# AT32F413xx register map
Vendor: Keil; Series: AT32F413; File version: 1.0
CPU: CM4 r0p1, little endian, no MPU, FPU, 4 interrupt priority bits
Registers are 32-bit, read-write, reset 0x0 unless marked. A register's access mark holds for its fields unless they carry their own. Offsets are from the block's base; [hi:lo] are bit positions; {n}, {i} and the like mark numbered series; 'fields as' and 'values as' point back to an identical list.

## UART4 — Universal asynchronous receiver transmitter
Base 0x40004C00
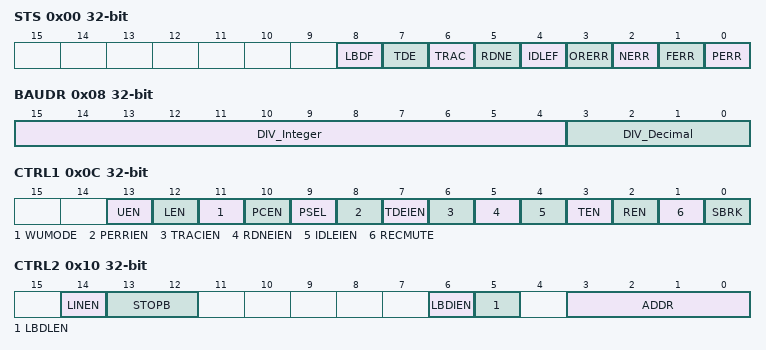
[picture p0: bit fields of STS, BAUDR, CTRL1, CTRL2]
0x00 STS — UART4_STS
  [8] LBDF — LIN break detection flag
  [7] TDE ro — Transmit data register empty
  [6] TRAC — Transmission complete
  [5] RDNE — Read data register not empty
  [4] IDLEF ro — IDLE line detected
  [3] ORERR ro — Overrun error
  [2] NERR ro — Noise error flag
  [1] FERR ro — Framing error
  [0] PERR ro — Parity error
0x04 DT — UART4_DR
  [8:0] DT — DR
0x08 BAUDR — UART4_BAUDR
  [15:4] DIV_Integer — DIV_Mantissa
  [3:0] DIV_Decimal — DIV_Fraction
0x0C CTRL1 — UART4_CTRL1
  [13] UEN — USART enable
  [12] LEN — Word length
  [11] WUMODE — Wakeup method
  [10] PCEN — Parity control enable
  [9] PSEL — Parity selection
  [8] PERRIEN — PE interrupt enable
  [7] TDEIEN — TXE interrupt enable
  [6] TRACIEN — Transmission complete interrupt enable
  [5] RDNEIEN — RXNE interrupt enable
  [4] IDLEIEN — IDLE interrupt enable
  [3] TEN — Transmitter enable
  [2] REN — Receiver enable
  [1] RECMUTE — Receiver wakeup
  [0] SBRK — Send break
0x10 CTRL2 — UART4_CTRL2
  [14] LINEN — LIN mode enable
  [13:12] STOPB — STOP bits
  [6] LBDIEN — LIN break detection interrupt enable
  [5] LBDLEN — lin break detection length
  [3:0] ADDR — Address of the USART node
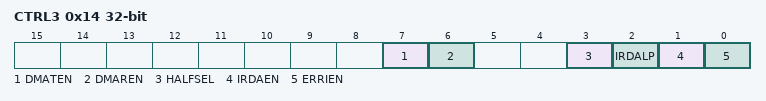
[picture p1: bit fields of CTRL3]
0x14 CTRL3 — UART4_CTRL3
  [7] DMATEN — DMA enable transmitter
  [6] DMAREN — DMA enable receiver
  [3] HALFSEL — Half-duplex selection
  [2] IRDALP — IrDA low-power
  [1] IRDAEN — IrDA mode enable
  [0] ERRIEN — Error interrupt enable

## UART5 — Universal asynchronous receiver transmitter
Base 0x40005000
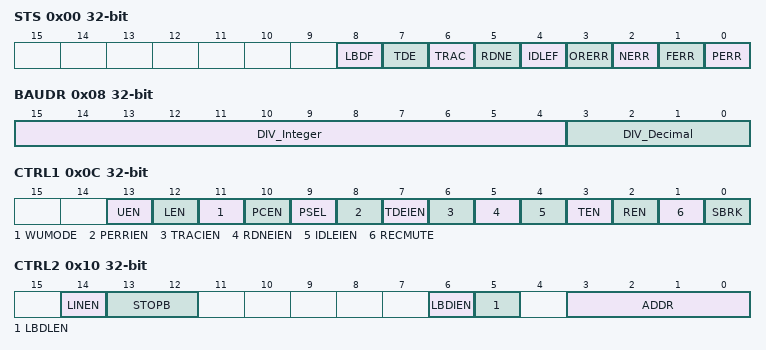
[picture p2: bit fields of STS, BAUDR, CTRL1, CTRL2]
0x00 STS — UART4_STS
  [8] LBDF — LBD
  [7] TDE ro — TXE
  [6] TRAC — TC
  [5] RDNE — RXNE
  [4] IDLEF ro — IDLE
  [3] ORERR ro — ORE
  [2] NERR ro — NE
  [1] FERR ro — FE
  [0] PERR ro — PE
0x04 DT — UART4_DT
  [8:0] DT
0x08 BAUDR — UART4_BAUDR
  [15:4] DIV_Integer — DIV_Mantissa
  [3:0] DIV_Decimal — DIV_Fraction
0x0C CTRL1 — UART4_CTRL1
  [13] UEN — UE
  [12] LEN — M
  [11] WUMODE — WAKE
  [10] PCEN — PCE
  [9] PSEL — PS
  [8] PERRIEN — PEIE
  [7] TDEIEN — TXEIE
  [6] TRACIEN — TCIE
  [5] RDNEIEN — RXNEIE
  [4] IDLEIEN — IDLEIE
  [3] TEN — TE
  [2] REN — RE
  [1] RECMUTE — RWU
  [0] SBRK — SBK
0x10 CTRL2 — UART4_CTRL2
  [14] LINEN
  [13:12] STOPB — STOP
  [6] LBDIEN — LBDIE
  [5] LBDLEN — LBDL
  [3:0] ADDR — ADD
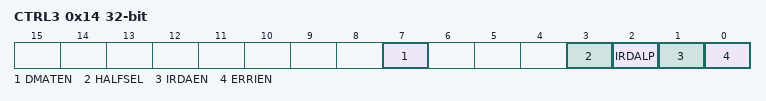
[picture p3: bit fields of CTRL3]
0x14 CTRL3 — UART4_CTRL3
  [7] DMATEN — DMA enable transmitter
  [3] HALFSEL — Half-duplex selection
  [2] IRDALP — IrDA low-power
  [1] IRDAEN — IrDA mode enable
  [0] ERRIEN — Error interrupt enable

## CRC — CRC calculation unit
Base 0x40023000
0x00 DT reset 0xFFFFFFFF — Data register
  [31:0] DR — Data Register
0x04 IDT — Independent Data register
  [7:0] IDR
0x08 CTRL — Control register
  [0] RESET — Reset bit

## FMC
Base 0x40022000
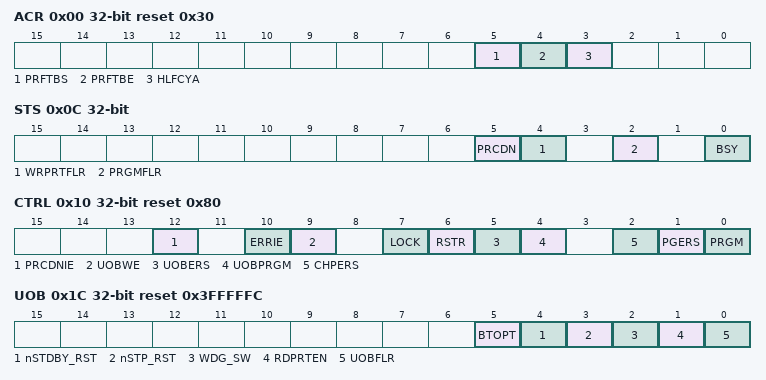
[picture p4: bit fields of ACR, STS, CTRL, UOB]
0x00 ACR reset 0x30 — Flash access control register
  [5] PRFTBS ro — Prefetch buffer status
  [4] PRFTBE — Prefetch buffer enable
  [3] HLFCYA — Flash half cycle access enable
0x04 FCKEY wo — Flash key register
  [31:0] KEY — FPEC key
0x08 OPTKEYR wo — Flash option key register
  [31:0] OPTKEYR — Option byte key
0x0C STS — Status register
  [5] PRCDN — End of operation
  [4] WRPRTFLR — Write protection error
  [2] PRGMFLR — Programming error
  [0] BSY ro — Busy
0x10 CTRL reset 0x80 — Control register
  [12] PRCDNIE — End of operation interrupt enable
  [10] ERRIE — Error interrupt enable
  [9] UOBWE — Option bytes write enable
  [7] LOCK
  [6] RSTR — Start
  [5] UOBERS — Option byte erase
  [4] UOBPRGM — Option byte programming
  [2] CHPERS — Mass Erase
  [1] PGERS — Page Erase
  [0] PRGM — Programming
0x14 ADDR wo — Flash address register
  [31:0] TA — Flash Address
0x1C UOB ro reset 0x3FFFFFC — Option byte register
  [5] BTOPT
  [4] nSTDBY_RST
  [3] nSTP_RST
  [2] WDG_SW
  [1] RDPRTEN — Read protection
  [0] UOBFLR — Option byte error
0x20 WRPRT ro reset 0xFFFFFFFF — Write protection register
  [31:0] WRPRTBMP — Write protect
0x44 FCKEY2 wo — Fpec key
  [31:0] KEY — Write protect
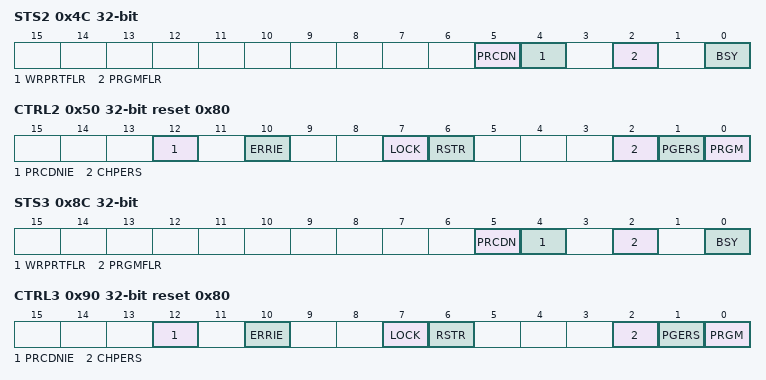
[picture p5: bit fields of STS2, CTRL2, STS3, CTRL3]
0x4C STS2 — Status
  [5] PRCDN
  [4] WRPRTFLR — nSTDBY_RST
  [2] PRGMFLR
  [0] BSY ro — Option byte error
0x50 CTRL2 reset 0x80 — Control register
  [12] PRCDNIE — End of operation interrupt enable
  [10] ERRIE — Error interrupt enable
  [7] LOCK
  [6] RSTR — Start
  [2] CHPERS — Mass Erase
  [1] PGERS — Page Erase
  [0] PRGM — Programming
0x54 ADDR2 wo — Flash address register
  [31:0] TA — Flash Address
0x84 FCKEY3 wo — Fpec key
  [31:0] KEY — Write protect
0x88 SELECT wo
  [31:0] SELECT — Write protect
0x8C STS3 — Status
  fields as STS2
0x90 CTRL3 reset 0x80 — Control register
  fields as CTRL2
0x94 ADDR3 wo — Flash address register
  [31:0] TA — Flash Address
0x98 DA
  [31:0] FDA
0xCC SLIB_STS0
  [3] FSLIB_SLIB_EN read
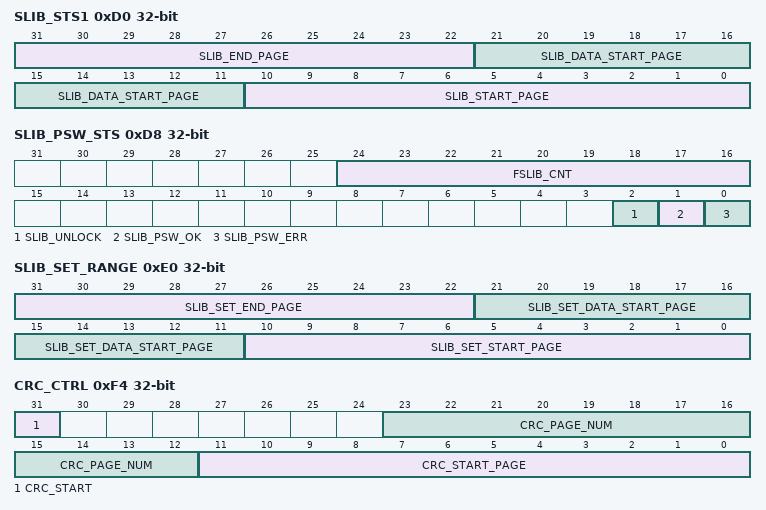
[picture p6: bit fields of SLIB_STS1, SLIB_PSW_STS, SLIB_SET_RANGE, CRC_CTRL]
0xD0 SLIB_STS1
  [31:22] SLIB_END_PAGE read — SLIB End Page Number
  [21:11] SLIB_DATA_START_PAGE read — SLIB Data Start Page Number
  [10:0] SLIB_START_PAGE read — SLIB Start Page Number
0xD4 SLIB_PSW_CLR write — SLIB password register
  [31:0] FSLIB_PSW
0xD8 SLIB_PSW_STS — SLIB password state register
  [24:16] FSLIB_CNT read — Counter of remaining SLIB CFG
  [2] SLIB_UNLOCK read
  [1] SLIB_PSW_OK read — SLIB password match
  [0] SLIB_PSW_ERR read — SLIB password mismatch
0xDC SLIB_SET_PSW write — Configure SLIB password
  [31:0] FSLIB_SET_PSW
0xE0 SLIB_SET_RANGE write — Configure SLIB page range
  [31:22] SLIB_SET_END_PAGE — SLIB End Page Number, Valid input: 0~511
  [21:11] SLIB_SET_DATA_START_PAGE — SLIB Data Start Page Number, Valid input: 0~511, 0 means no data area
  [10:0] SLIB_SET_START_PAGE — SLIB Start Page Number, Valid input: 0~511
0xF0 SLIB_KEYR write — SLIB unlock key register
  [31:0] FSLIB_KEYR
0xF4 CRC_CTRL wo — Flash crc ctrl register
  [31] CRC_START, [23:12] CRC_PAGE_NUM, [11:0] CRC_START_PAGE
0xF8 CRC_OUTR ro — Flash crc output register
  [31:0] CRC_OUT

## NVIC — Nested Vectored Interrupt Controller
Base 0xE000E000
0x04 ICTR ro — Interrupt Controller Type Register
  [3:0] INTLINESNUM — Total number of interrupt lines in groups
0x100 ISER0 — Interrupt Set-Enable Register
  [31:0] SETENA
0x104 ISER1 — Interrupt Set-Enable Register
  [31:0] SETENA
0x180 ICER0 — Interrupt Clear-Enable Register
  [31:0] CLRENA
0x184 ICER1 — Interrupt Clear-Enable Register
  [31:0] CLRENA
0x200 ISPR0 — Interrupt Set-Pending Register
  [31:0] SETPEND
0x204 ISPR1 — Interrupt Set-Pending Register
  [31:0] SETPEND
0x280 ICPR0 — Interrupt Clear-Pending Register
  [31:0] CLRPEND
0x284 ICPR1 — Interrupt Clear-Pending Register
  [31:0] CLRPEND
0x300 IABR0 ro — Interrupt Active Bit Register
  [31:0] ACTIVE
0x304 IABR1 ro — Interrupt Active Bit Register
  [31:0] ACTIVE
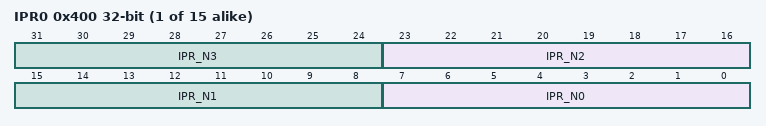
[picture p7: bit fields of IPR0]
{0x400+4i} IPR{i} (i=0..14) — Interrupt Priority Register
  [8n+7:8n] IPR_N{n} (n=0..3)
0xF00 STIR wo — Software Triggered Interrupt Register
  [8:0] INTID — interrupt to be triggered

## USBDEV — Universal serial bus full-speed device interface
Base 0x40005C00
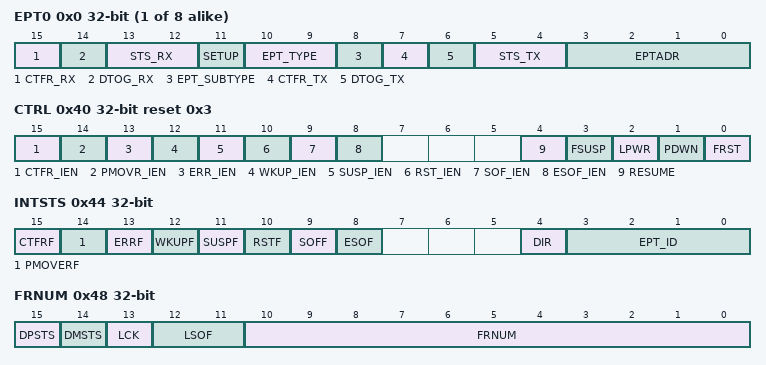
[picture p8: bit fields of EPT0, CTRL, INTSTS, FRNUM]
{0x0+4i} EPT{i} (i=0..7) — endpoint {i} register
  [15] CTFR_RX — Correct transfer for reception
  [14] DTOG_RX — Data Toggle, for reception transfers
  [13:12] STS_RX — Status bits, for reception transfers
  [11] SETUP — Setup transaction completed
  [10:9] EPT_TYPE — Endpoint type
  [8] EPT_SUBTYPE — Endpoint kind
  [7] CTFR_TX — Correct Transfer for transmission
  [6] DTOG_TX — Data Toggle, for transmission transfers
  [5:4] STS_TX — Status bits, for transmission transfers
  [3:0] EPTADR — Endpoint address
0x40 CTRL reset 0x3 — control register
  [15] CTFR_IEN — Correct transfer interrupt mask
  [14] PMOVR_IEN — Packet memory area over / underrun interrupt mask
  [13] ERR_IEN — Error interrupt mask
  [12] WKUP_IEN — Wakeup interrupt mask
  [11] SUSP_IEN — Suspend mode interrupt mask
  [10] RST_IEN — USB reset interrupt mask
  [9] SOF_IEN — Start of frame interrupt mask
  [8] ESOF_IEN — Expected start of frame interrupt mask
  [4] RESUME — Resume request
  [3] FSUSP — Force suspend
  [2] LPWR — Low-power mode
  [1] PDWN — Power down
  [0] FRST — Force USB Reset
0x44 INTSTS — interrupt status register
  [15] CTFRF — Correct transfer
  [14] PMOVERF — Packet memory area over / underrun
  [13] ERRF — Error
  [12] WKUPF — Wakeup
  [11] SUSPF — Suspend mode request
  [10] RSTF — reset request
  [9] SOFF — start of frame
  [8] ESOF — Expected start frame
  [4] DIR — Direction of transaction
  [3:0] EPT_ID — Endpoint Identifier
0x48 FRNUM — frame number register
  [15] DPSTS — Receive data + line status
  [14] DMSTS — Receive data - line status
  [13] LCK — Locked
  [12:11] LSOF — Lost SOF
  [10:0] FRNUM — Frame number
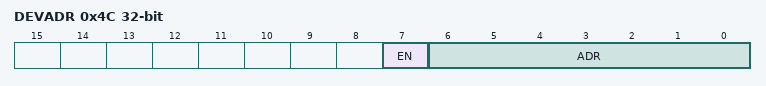
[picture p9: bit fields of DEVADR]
0x4C DEVADR — device address
  [7] EN — Enable function
  [6:0] ADR — Device address
0x50 BUFTBL — Buffer table address
  [15:3] ADR — Buffer table
0x60 SOFEN — SOF control register
  [0] SOFOUTEN — SOF output enable
